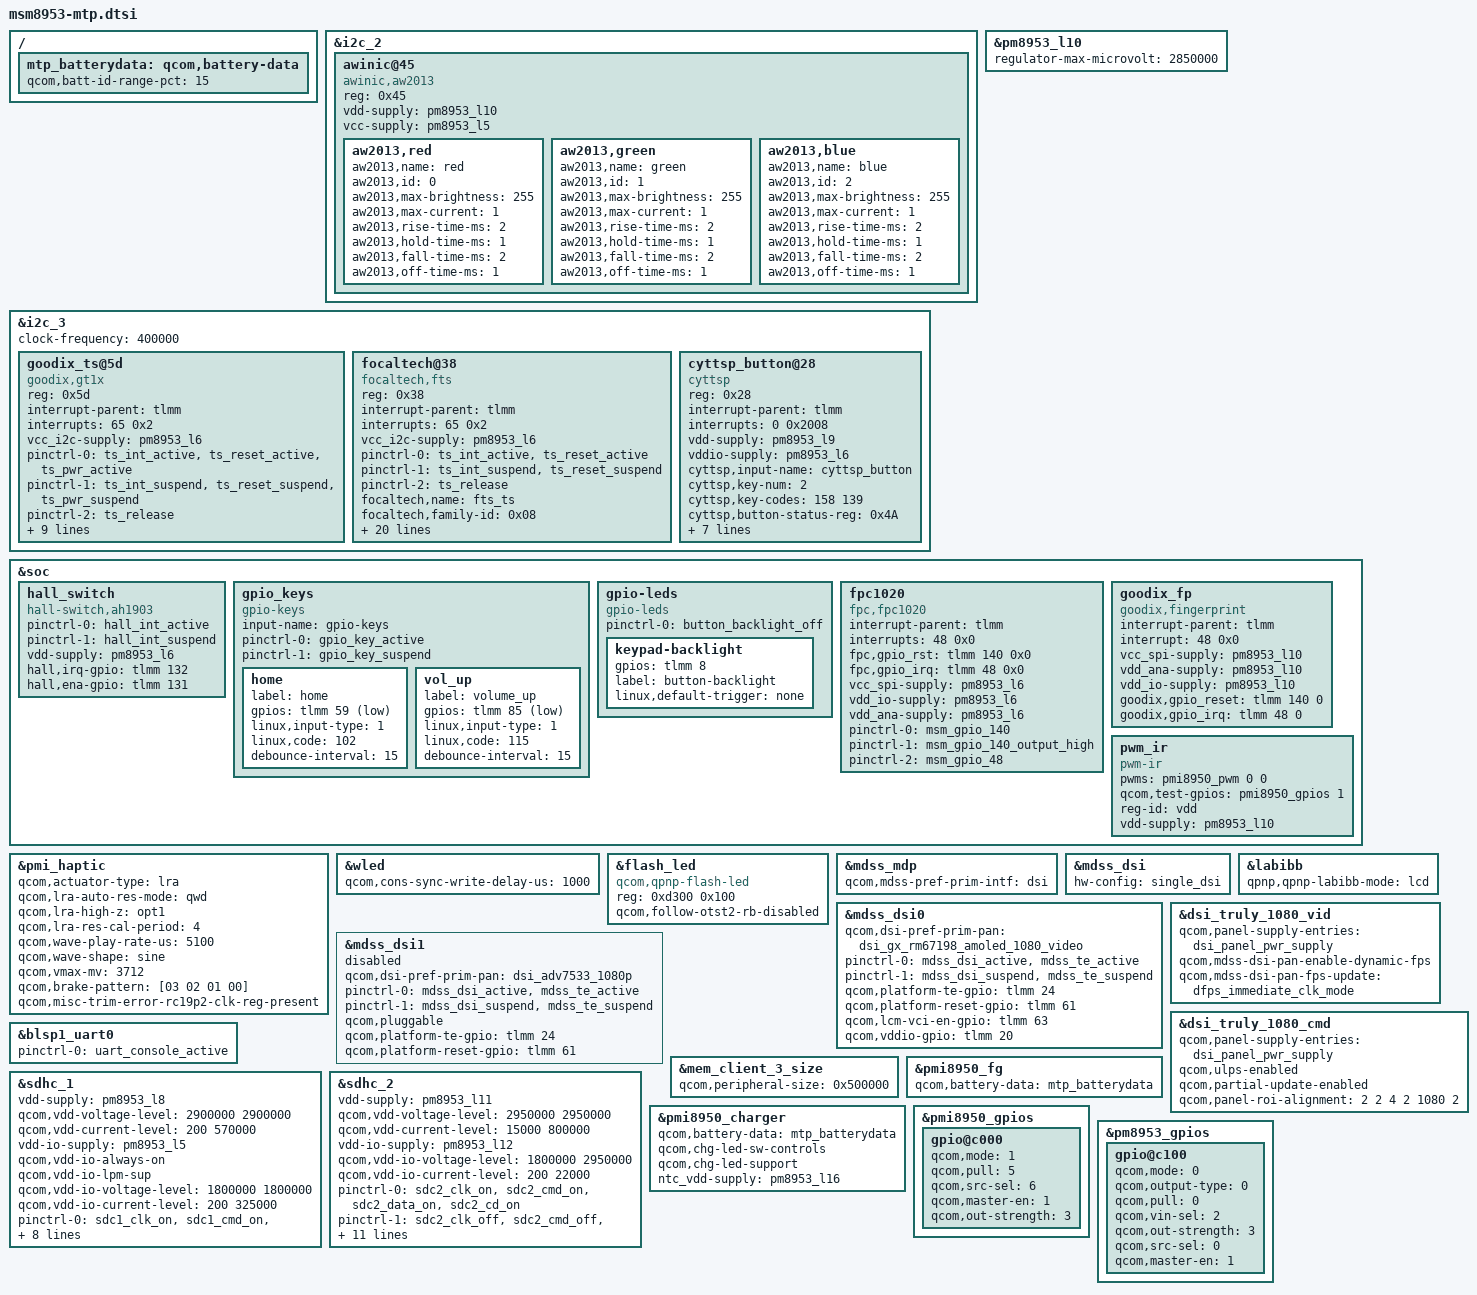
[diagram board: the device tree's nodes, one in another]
/*
 * Copyright (c) 2015-2016, The Linux Foundation. All rights reserved.
 *
 * This program is free software; you can redistribute it and/or modify
 * it under the terms of the GNU General Public License version 2 and
 * only version 2 as published by the Free Software Foundation.
 *
 * This program is distributed in the hope that it will be useful,
 * but WITHOUT ANY WARRANTY; without even the implied warranty of
 * MERCHANTABILITY or FITNESS FOR A PARTICULAR PURPOSE.  See the
 * GNU General Public License for more details.
 */

#include "msm8953-pinctrl.dtsi"
/*#include "msm8953-audio-mtp.dtsi"*/
#include "msm8953-camera-sensor-mtp.dtsi"


&i2c_2 {

               awinic@45 { /* Breath Light-Driven */
                       compatible = "awinic,aw2013";
                       reg = <0x45>;
                       vdd-supply = <&pm8953_l10>;
                       vcc-supply = <&pm8953_l5>; 
		 aw2013,red {
			aw2013,name = "red";
			aw2013,id = <0>;
			aw2013,max-brightness = <255>;
			aw2013,max-current = <1>;
			aw2013,rise-time-ms = <2>;
			aw2013,hold-time-ms = <1>;
			aw2013,fall-time-ms = <2>;
			aw2013,off-time-ms = <1>;
		};
		aw2013,green {
			aw2013,name = "green";
			aw2013,id = <1>;
			aw2013,max-brightness = <255>;
			aw2013,max-current = <1>;
			aw2013,rise-time-ms = <2>;
			aw2013,hold-time-ms = <1>;
			aw2013,fall-time-ms = <2>;
			aw2013,off-time-ms = <1>;
		};
		aw2013,blue {
			aw2013,name = "blue";
			aw2013,id = <2>;
			aw2013,max-brightness = <255>;
			aw2013,max-current = <1>;
			aw2013,rise-time-ms = <2>;
			aw2013,hold-time-ms = <1>;
			aw2013,fall-time-ms = <2>;
			aw2013,off-time-ms = <1>;
		};
               };
};




&i2c_3 {
	status = "okay";
	clock-frequency = <400000>;
	goodix_ts@5d{
		compatible = "goodix,gt1x";
		reg = <0x5d>;
		interrupt-parent = <&tlmm>;
		interrupts = <65 0x2>;
		//				vdd-supply = <&pm8953_l9>;
		vcc_i2c-supply = <&pm8953_l6>;
		/* pins used by touchscreen */
		pinctrl-names = "pmx_ts_active","pmx_ts_suspend","pmx_ts_release";
		pinctrl-0 = <&ts_int_active &ts_reset_active &ts_pwr_active>;
		pinctrl-1 = <&ts_int_suspend &ts_reset_suspend &ts_pwr_suspend>;
		pinctrl-2 = <&ts_release>;				
		//				goodix,family-id = <0x06>;
		//				goodix,product-id = "1011";
		goodix,reset-gpio = <&tlmm 64 0x00>;
		goodix,power_ldo-gpio = <&tlmm 21 0x00>;
		goodix,irq-gpio = <&tlmm 65 0x00>;
		//				goodix,display-coords = <0 1200 0 1920>;
		//				goodix,panel-coords = <0 1200 0 1920>;
		//				goodix,button-map = <158 102 139>;
		//goodix,fw-auto-update;
		/*goodix,force-update;*/
		goodix,i2c-pull-up;
		goodix,dbl_clk_wakeup;
		goodix,default-config0 = [
					FF 38 04 80 07 0A 0D 00 01 40
					00 0B 78 64 53 04 00 00 00 00
					28 00 00 00 08 04 00 02 28 78
					00 00 00 41 00 00 00 9B 00 00
					00 00 00 00 00 00 89 28 1E 4E
					50 85 0C 38 6D 38 DD 03 26 00
					05 5A 87 00 4F 55 32 01 04 68
					61 6E 68 75 70 75 77 8B 7F 9C
					00 00 00 00 00 00 00 00 00 00
					00 00 00 23 23 00 00 0F 0F 04
					0E 88 88 88 08 00 00 00 00 00
					00 00 00 00 04 00 00 00 00 00
					00 00 00 00 00 00 00 00 00 00
					00 00 00 00 00 00 00 00 3C 37
					01 02 03 04 05 06 07 08 09 0A
					0B 0C 0D 0E 0F 10 12 13 14 15
					16 17 18 19 1A 1B 1C 1D 1E 1F
					FF 00 01 02 03 04 05 06 07 08
					09 0A 0B 0C 0D 0E 0F 10 12 00
					00 00 00 00 00 00 00 00 00 00
					00 00 00 00 00 00 00 00 00 00
					00 00 00 00 00 00 00 00 00 00
					00 00 13 1E 6D 01 00 00 00 0A
					00 00 00 D0 07 50 36 27 01
		];	
		goodix,charger-config2 = [
					FF 38 04 80 07 0A 0D 00 01 40
					00 0B 78 64 53 04 00 00 00 00
					28 00 00 00 08 04 00 02 28 78
					00 00 00 41 00 00 00 9B 00 00
					00 00 00 00 00 00 89 28 1E 4E
					50 85 0C 38 6D 38 DD 03 26 00
					05 5A 87 00 4F 55 32 01 04 68
					61 6E 68 75 70 75 77 8B 7F 9C
					00 00 00 00 00 00 00 00 00 00
					00 00 00 23 23 00 00 0F 0F 04
					0E 88 88 88 08 00 00 00 00 00
					00 00 00 00 04 00 00 00 00 00
					00 00 00 00 00 00 00 00 00 00
					00 00 00 00 00 00 00 00 3C 37
					01 02 03 04 05 06 07 08 09 0A
					0B 0C 0D 0E 0F 10 12 13 14 15
					16 17 18 19 1A 1B 1C 1D 1E 1F
					FF 00 01 02 03 04 05 06 07 08
					09 0A 0B 0C 0D 0E 0F 10 12 00
					00 00 00 00 00 00 00 00 00 00
					00 00 00 00 00 00 00 00 00 00
					00 00 00 00 00 00 00 00 00 00
					00 00 13 1E 6D 01 00 00 00 0A
					00 00 00 D0 07 50 36 27 01
		];
	};
		focaltech@38{
			compatible = "focaltech,fts";
			reg = <0x38>;
			interrupt-parent = <&tlmm>;
			interrupts = <65 0x2>;
			vcc_i2c-supply = <&pm8953_l6>;
			/* pins used by touchscreen */
			pinctrl-names = "pmx_ts_active","pmx_ts_suspend",
							"pmx_ts_release";
			pinctrl-0 = <&ts_int_active &ts_reset_active>;
			pinctrl-1 = <&ts_int_suspend &ts_reset_suspend>;
			pinctrl-2 = <&ts_release>;
			focaltech,name = "fts_ts";
			focaltech,family-id = <0x08>;
			focaltech,reset-gpio = <&tlmm 64 0x01>;
			focaltech,power_ldo-gpio = <&tlmm 21 0x00>;
			focaltech,irq-gpio = <&tlmm 65 0x02>;
			focaltech,display-coords = <0 0 1080 1920>;
			focaltech,max-touch-number = <10>;
/*			focaltech,have-key;
			focaltech,key-number = <3>;
			focaltech,keys = <139 102 158>;
			focaltech,key-y-coord = <1350>;
			focaltech,key-x-coords = <180 350 540>;*/
			focaltech,no-force-update;
			focaltech,i2c-pull-up;
			focaltech,group-id = <1>;
			focaltech,hard-reset-delay-ms = <20>;
			focaltech,soft-reset-delay-ms = <200>;
			focaltech,num-max-touches = <5>;
			focaltech,fw-delay-aa-ms = <30>;
			focaltech,fw-delay-55-ms = <30>;
			focaltech,fw-upgrade-id1 = <0x79>;
			focaltech,fw-upgrade-id2 = <0x08>;
			focaltech,fw-delay-readid-ms = <10>;
			focaltech,fw-delay-era-flsh-ms = <2000>;
			focaltech,fw-auto-cal;
			focaltech,resume-in-workqueue;
			focaltech,ignore-id-check;
		};
	
	
	           cyttsp_button@28 {
			/*compatible = "cyttsp,button_touch";*/
			compatible = "cyttsp";
			reg = <0x28>;
					interrupt-parent = <&tlmm>;
		interrupts = <0 0x2008>;
			vdd-supply = <&pm8953_l9>;
			vddio-supply = <&pm8953_l6>;
	cyttsp,input-name = "cyttsp_button";
	cyttsp,key-num = <2>;
	/*139: menu; 158: back*/
	cyttsp,key-codes = <158 139>;
	cyttsp,button-status-reg = <0x4A>;	
	cyttsp,bootloader-addr = <0x56>;
	cyttsp,irq-gpio = <&tlmm 0 0x2008>;
	cyttsp,config-array-size = <1>;
	cyttsp,standby-reg = <0x01>;		   
	cyttsp,hw-version = <0x84>;
	cyttsp,fw-name = "Xiaomi_H3C_bootloadable_FW_V5.cyacd";
	  
	  
	};
	
	
};

&pm8953_l10 {
	regulator-max-microvolt = <2850000>;
};

&soc {
	hall_switch {
		compatible = "hall-switch,ah1903";
		pinctrl-names = "hall_active","hall_suspend";
		pinctrl-0 = <&hall_int_active>;
		pinctrl-1 = <&hall_int_suspend>;
		vdd-supply = <&pm8953_l6>;
		interrupt-names = "hall-irq";
		hall,irq-gpio = <&tlmm 132 0>;
		hall,ena-gpio = <&tlmm 131 0>;
	};

	gpio_keys {
		compatible = "gpio-keys";
		input-name = "gpio-keys";
		pinctrl-names = "tlmm_gpio_key_active","tlmm_gpio_key_suspend";
		pinctrl-0 = <&gpio_key_active>;
		pinctrl-1 = <&gpio_key_suspend>;


		home {
			label = "home";
			gpios = <&tlmm 59 0x1>;
			linux,input-type = <1>;
			linux,code = <102>;
			debounce-interval = <15>;
		};

		vol_up {
			label = "volume_up";
			gpios = <&tlmm 85 0x1>;
			linux,input-type = <1>;
			linux,code = <115>;
			debounce-interval = <15>;
		};

	};
gpio-leds {
		compatible = "gpio-leds";
		status = "okay";
		pinctrl-names = "default";
		pinctrl-0 = <&button_backlight_off>;
		keypad-backlight {
			gpios = <&tlmm 8 0x00>;
			label = "button-backlight";
			linux,default-trigger = "none";
		};
		
	};

	fpc1020 {
		status = "ok";
		compatible = "fpc,fpc1020";
		interrupt-parent = <&tlmm>;
		interrupts = <48 0x0>;
		fpc,gpio_rst    = <&tlmm 140 0x0>;
		fpc,gpio_irq    = <&tlmm 48 0x0>;
		vcc_spi-supply  = <&pm8953_l6>;
		vdd_io-supply   = <&pm8953_l6>;
		vdd_ana-supply  = <&pm8953_l6>;

		pinctrl-names = "fpc1020_reset_reset",
			"fpc1020_reset_active",
			"fpc1020_irq_active";

		pinctrl-0 = <&msm_gpio_140>;
		pinctrl-1 = <&msm_gpio_140_output_high>;
		pinctrl-2 = <&msm_gpio_48>;
	};

	goodix_fp {
		compatible = "goodix,fingerprint";
		interrupt-parent = <&tlmm>;
		interrupt = <48 0x0>;
		vcc_spi-supply = <&pm8953_l10>;
		vdd_ana-supply = <&pm8953_l10>;
		vdd_io-supply = <&pm8953_l10>;
		goodix,gpio_reset = <&tlmm 140 0>;
		goodix,gpio_irq = <&tlmm 48 0>;
		/*goodix,gpio_pwr = <&tlmm 0 0>;*/
	};

	pwm_ir {
		compatible = "pwm-ir";
		pwms = <&pmi8950_pwm 0 0>;
		qcom,test-gpios = <&pmi8950_gpios 1 0>;
		reg-id = "vdd";
		vdd-supply = <&pm8953_l10>;
		//		use-timer;
	};


};

&pmi_haptic{
        status = "okay";
        qcom,actuator-type = "lra";  
        qcom,lra-auto-res-mode="qwd";        
        qcom,lra-high-z="opt1";                              
        qcom,lra-res-cal-period = <4>;                       
        qcom,wave-play-rate-us = <5100>;                         
        qcom,wave-shape = "sine";                                           
        qcom,vmax-mv = <3712>;                                       
        qcom,brake-pattern = [03 02 01 00];                               
        qcom,misc-trim-error-rc19p2-clk-reg-present;
};

&wled {
	qcom,cons-sync-write-delay-us = <1000>;
};

&flash_led {
	compatible = "qcom,qpnp-flash-led";
	reg = <0xd300 0x100>;
	qcom,follow-otst2-rb-disabled;
};

#include "msm8953-mdss-panels.dtsi"

&mdss_mdp {
	qcom,mdss-pref-prim-intf = "dsi";
};

&mdss_dsi {
	hw-config = "single_dsi";
};
    
&mdss_dsi0 {
	qcom,dsi-pref-prim-pan = <&dsi_gx_rm67198_amoled_1080_video>;
	pinctrl-names = "mdss_default", "mdss_sleep";
	pinctrl-0 = <&mdss_dsi_active &mdss_te_active>;
	pinctrl-1 = <&mdss_dsi_suspend &mdss_te_suspend>;

	qcom,platform-te-gpio = <&tlmm 24 0>;
	qcom,platform-reset-gpio = <&tlmm 61 0>;
	/*qcom,platform-bklight-en-gpio = <&tlmm 59 0>;*/
	qcom,lcm-vci-en-gpio = <&tlmm 63 0>;
	qcom,vddio-gpio = <&tlmm 20 0>;
};

&mdss_dsi1 {
	status = "disabled";
	qcom,dsi-pref-prim-pan = <&dsi_adv7533_1080p>;
	pinctrl-names = "mdss_default", "mdss_sleep";
	pinctrl-0 = <&mdss_dsi_active &mdss_te_active>;
	pinctrl-1 = <&mdss_dsi_suspend &mdss_te_suspend>;

	qcom,pluggable;
	qcom,platform-te-gpio = <&tlmm 24 0>;
	qcom,platform-reset-gpio = <&tlmm 61 0>;
	/*qcom,platform-bklight-en-gpio = <&tlmm 59 0>;*/
};

&labibb {
	status = "ok";
	qpnp,qpnp-labibb-mode = "lcd";
};

&dsi_truly_1080_vid {
	qcom,panel-supply-entries = <&dsi_panel_pwr_supply>;
	qcom,mdss-dsi-pan-enable-dynamic-fps;
	qcom,mdss-dsi-pan-fps-update = "dfps_immediate_clk_mode";
};

&dsi_truly_1080_cmd {
	qcom,panel-supply-entries = <&dsi_panel_pwr_supply>;
	qcom,ulps-enabled;
	qcom,partial-update-enabled;
	qcom,panel-roi-alignment = <2 2 4 2 1080 2>;
};

&blsp1_uart0 {
	status = "ok";
	pinctrl-names = "default";
	pinctrl-0 = <&uart_console_active>;
};

&mem_client_3_size {
	qcom,peripheral-size = <0x500000>;
};

&sdhc_1 {
	/* device core power supply */
	vdd-supply = <&pm8953_l8>;
	qcom,vdd-voltage-level = <2900000 2900000>;
	qcom,vdd-current-level = <200 570000>;

	/* device communication power supply */
	vdd-io-supply = <&pm8953_l5>;
	qcom,vdd-io-always-on;
	qcom,vdd-io-lpm-sup;
	qcom,vdd-io-voltage-level = <1800000 1800000>;
	qcom,vdd-io-current-level = <200 325000>;

	pinctrl-names = "active", "sleep";
	pinctrl-0 = <&sdc1_clk_on &sdc1_cmd_on &sdc1_data_on  &sdc1_rclk_on>;
	pinctrl-1 = <&sdc1_clk_off &sdc1_cmd_off &sdc1_data_off &sdc1_rclk_off>;

	qcom,clk-rates = <400000 20000000 25000000 50000000 100000000 192000000
								384000000>;
	qcom,nonremovable;
	qcom,bus-speed-mode = "HS400_1p8v", "HS200_1p8v", "DDR_1p8v";

	status = "ok";
};

&sdhc_2 {
	/* device core power supply */
	vdd-supply = <&pm8953_l11>;
	qcom,vdd-voltage-level = <2950000 2950000>;
	qcom,vdd-current-level = <15000 800000>;

	/* device communication power supply */
	vdd-io-supply = <&pm8953_l12>;
	qcom,vdd-io-voltage-level = <1800000 2950000>;
	qcom,vdd-io-current-level = <200 22000>;

	pinctrl-names = "active", "sleep";
	pinctrl-0 = <&sdc2_clk_on &sdc2_cmd_on &sdc2_data_on &sdc2_cd_on>;
	pinctrl-1 = <&sdc2_clk_off &sdc2_cmd_off &sdc2_data_off>;

	#address-cells = <0>;
	interrupt-parent = <&sdhc_2>;
	interrupts = <0 1 2>;
	#interrupt-cells = <1>;
	interrupt-map-mask = <0xffffffff>;
	interrupt-map = <0 &intc 0 125 0
		1 &intc 0 221 0
		2 &tlmm 133 0>;
	interrupt-names = "hc_irq", "pwr_irq", "status_irq";
	cd-gpios = <&tlmm 133 0x0>;

	qcom,clk-rates = <400000 20000000 25000000 50000000 100000000
								200000000>;
	qcom,bus-speed-mode = "SDR12", "SDR25", "SDR50", "DDR50", "SDR104";

	status = "ok";
};
/*
&pm8953_typec {
	ss-mux-supply = <&pm8953_l13>;
	qcom,ssmux-gpio = <&tlmm 139 GPIO_ACTIVE_HIGH>;
	pinctrl-names = "default";
	pinctrl-0 = <&typec_ssmux_config>;
};
*/
/{
	mtp_batterydata: qcom,battery-data {
		qcom,batt-id-range-pct = <15>;
		#include "batterydata-sunwoda-3300mah-4400mv.dtsi"
		#include "batterydata-coslight-3300mah-4400mv.dtsi"
	};
};

&pmi8950_fg {
	qcom,battery-data = <&mtp_batterydata>;
};

&pmi8950_charger {
	qcom,battery-data = <&mtp_batterydata>;
	qcom,chg-led-sw-controls;
	qcom,chg-led-support;
	ntc_vdd-supply = <&pm8953_l16>;
	//qcom,external-typec;
	//qcom,typec-psy-name = "typec";
};

&pmi8950_gpios{
	gpio@c000{
		status = "okay";
		qcom,mode = <1>;		/*DIGITAL OUT*/ 
		qcom,pull = <5>;		/*NO PULL*/
		qcom,src-sel = <6>; 		/*DTEST1 OUT*/
		qcom,master-en = <1>;		/*ENABLE GPIO*/ 
		qcom,out-strength = <3>;	/*Max strength current*/		   
	};
};

&pm8953_gpios {
	/* GPIO 2 (NFC_CLK_REQ) */
	gpio@c100 {
		qcom,mode = <0>;
		qcom,output-type = <0>;
		qcom,pull = <0>;
		qcom,vin-sel = <2>;
		qcom,out-strength = <3>;
		qcom,src-sel = <0>;
		qcom,master-en = <1>;
		status = "okay";
	};
};
